# ESP32S31_RADIO register map
Vendor: Espressif; Series: ESP32-S31; File version: 3.52
Registers are 32-bit, read-write, no defined reset value unless marked. A register's access mark holds for its fields unless they carry their own. Offsets are from the block's base; [hi:lo] are bit positions.

## PHY_ADC_DUMP_RECOVERED — Receive sample-dump words programmed by complete librftest adctrig and set_dump_mode. Dumped words are read back from 0x2f060000 as signed ten-bit components in bits 9:0 and 19:10 (complete print_dump_data and sampledeal); that aperture is not radio MMIO.
Base 0x20100000
0x8CC WORD_08CC_OPAQUE — Opaque: meaning not established. Complete set_dump_mode clears bits 22:19 in one fresh-read RMW before selecting the dump mode.
  [22:19] BITS_19_22_OPAQUE — Opaque: meaning not established. Four bits cleared by complete set_dump_mode for every mode.
0x20B4 WORD_20B4_OPAQUE — Opaque: meaning not established. One path of the selector jump table of complete adctrig clears bit 0 before programming the dump source; the analysis does not resolve which selector values take that path.
  [0] BIT_0_OPAQUE — Opaque: meaning not established. Cleared by one selector path of complete adctrig.
0x70B8 WORD_70B8_OPAQUE — Opaque: meaning not established. Complete set_dump_mode replaces bits 2:0 in one fresh-read RMW.
  [2:0] BITS_0_2_OPAQUE — Opaque: meaning not established. Complete set_dump_mode writes one for mode zero and zero for every other mode.
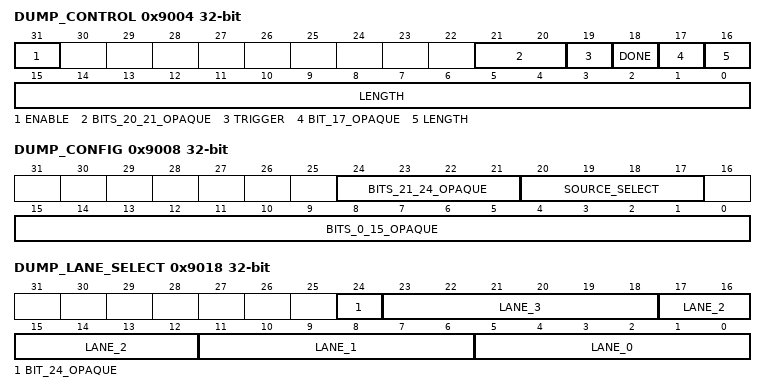
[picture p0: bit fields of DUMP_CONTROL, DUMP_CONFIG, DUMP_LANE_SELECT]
0x9004 DUMP_CONTROL — Project-assigned name. Sample-dump length, start and completion word. Complete adctrig programs LENGTH, clears bits 17 and 21:20, sets ENABLE, pulses TRIGGER for selector zero, polls DONE with a bounded wait and finally clears ENABLE.
  [31] ENABLE — Project-assigned name. Dump enable: complete adctrig sets this bit before starting the dump and clears it after the completion wait.
  [21:20] BITS_20_21_OPAQUE — Opaque: meaning not established. Cleared by complete adctrig before the dump starts.
  [19] TRIGGER — Project-assigned name. Software dump start: complete adctrig sets and then clears this bit for selector zero after setting ENABLE; selector twelve starts Bluetooth reception instead.
  [18] DONE — Project-assigned name. Dump completion: complete adctrig polls this bit after starting the dump and stops waiting once it is set or its 1,000,000-count bound of WIFI_MAC_LOCAL_TIME.COUNTER elapses.
  [17] BIT_17_OPAQUE — Opaque: meaning not established. Cleared by complete adctrig after LENGTH is written.
  [16:0] LENGTH — Project-assigned name. Number of dump words: complete adctrig writes its first argument plus one.
0x9008 DUMP_CONFIG — Project-assigned name. Sample-dump source and rate word. Complete adctrig replaces bits 24:21 at entry, replaces SOURCE_SELECT on one selector path and reads the whole word after the completion wait.
  [24:21] BITS_21_24_OPAQUE — Opaque: meaning not established. Complete adctrig writes half its fourth argument, or zero when that argument is below two.
  [20:17] SOURCE_SELECT — Project-assigned name. Dump source: one selector path of complete adctrig replaces these bits with its selector argument.
  [15:0] BITS_0_15_OPAQUE — Opaque: meaning not established. Read by complete adctrig after the completion wait; it prints the low sixteen bits.
0x9018 DUMP_LANE_SELECT — Project-assigned name. Four six-bit dump lane selectors and an enable bit, programmed by complete adctrig: 24, 25, 26 and 27 by default, with other values for selector arguments 11 and 12.
  [24] BIT_24_OPAQUE — Opaque: meaning not established. Set by complete adctrig after the lane selectors.
  [23:18] LANE_3 — Project-assigned name. Fourth lane selector; complete adctrig writes 27 by default.
  [17:12] LANE_2 — Project-assigned name. Third lane selector; complete adctrig writes 26 by default.
  [11:6] LANE_1 — Project-assigned name. Second lane selector; complete adctrig writes 25 by default.
  [5:0] LANE_0 — Project-assigned name. First lane selector; complete adctrig writes 24 by default.
